# SAMA7D65D2GN8 register map
Vendor: Microchip Technology; Series: SAMA7D6; File version: 0
Registers are 32-bit, read-write, reset 0x0 unless marked. A register's access mark holds for its fields unless they carry their own. Offsets are from the block's base; [hi:lo] are bit positions; 'fields as' and 'values as' point back to an identical list.

## TCPCA — Battery Charging and Type-C Port Controller
Base 0xE083C000; register names take the prefix TCPC_
Same registers: TCPCB 0xE0840000
0x00 VID 16-bit ro reset 0x4D8 — Vendor ID Register
  [15:0] VID — Vendor ID
0x02 PID 16-bit ro reset 0xFFF — Product ID Register
  [15:0] PID — Product ID
0x04 DID 16-bit ro reset 0x100 — Device ID Register
  [15:0] DID — Device ID
0x06 UTCR 16-bit ro reset 0x102 — USB Type-C Rev Register
  [15:0] UTCR — USB Type-C Revision
0x08 UPDR 16-bit ro — USB PD Rev Ver Register
  [15:0] UPDR — USB-PD Specification Revision and Version
0x0A PDIR 16-bit ro reset 0x1012 — PD Interface Rev Register
  [15:0] PDIR — USB-Port Controller Interface Specification Revision
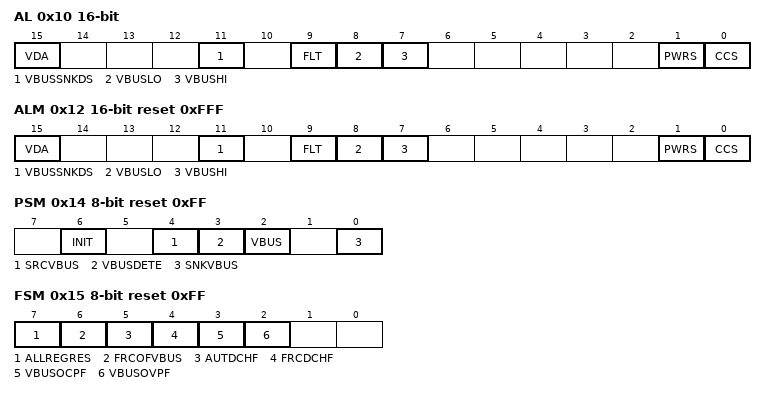
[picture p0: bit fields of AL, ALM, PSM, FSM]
0x10 AL 16-bit — Alert Register
  [15] VDA — Vendor Defined Alert (clear on write '1')
    0=No vendor-defined alert has been detected; 1=A vendor-defined alert has been detected
  [11] VBUSSNKDS — VBUS Sink Disconnect Detected (clear on write '1')
    0=No VBUS sink disconnect threshold crossing has been detected; 1=A VBUS sink disconnect threshold crossing has been detected
  [9] FLT — Fault (clear on write '1')
    0=No fault has occurred; 1=A fault has occurred. Read TCPC_FS.
  [8] VBUSLO — VBUS Voltage Alarm Low (clear on write '1')
    0=A low-voltage alarm has not occurred; 1=A low-voltage alarm has occurred
  [7] VBUSHI — VBUS Voltage Alarm High (clear on write '1')
    0=A high-voltage alarm has not occurred; 1=A high-voltage alarm has occurred
  [1] PWRS — Power Status (clear on write '1')
    0=Power status not changed; 1=Power status changed
  [0] CCS — CC Status (clear on write '1')
    0=CC status not changed; 1=CC status changed
0x12 ALM 16-bit reset 0xFFF — Alert Mask Register
  [15] VDA — Vendor Defined Alert Interrupt Mask
  [11] VBUSSNKDS — VBUS Sink Disconnect Detected Interrupt Mask
  [9] FLT — Fault Interrupt Mask
  [8] VBUSLO — VBUS Voltage Alarm Low Interrupt Mask
  [7] VBUSHI — VBUS Voltage Alarm High Interrupt Mask
  [1] PWRS — Power Status Interrupt Mask
  [0] CCS — CC Status Interrupt Mask
0x14 PSM 8-bit reset 0xFF — Power Status Mask Register
  [6] INIT — TCPC Initialization Interrupt Mask
  [4] SRCVBUS — Sourcing VBUS Interrupt Mask
  [3] VBUSDETE — VBUS Present Detection Interrupt Mask
  [2] VBUS — VBUS Present Interrupt Mask
  [0] SNKVBUS — Sinking VBUS Interrupt Mask
0x15 FSM 8-bit reset 0xFF — Fault Status Mask Register
  [7] ALLREGRES — All Registers Reset To Default Interrupt Mask
  [6] FRCOFVBUS — Force Off VBUS Interrupt Mask
  [5] AUTDCHF — Auto Discharge Failed Interrupt Mask
  [4] FRCDCHF — Force Discharge Failed Interrupt Mask
  [3] VBUSOCPF — Internal or External OCP VBUS Over Current Protection Fault Interrupt Mask
  [2] VBUSOVPF — Internal or External OVP VBUS Over Voltage Protection Fault Interrupt Mask
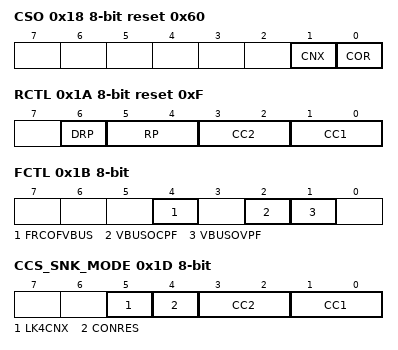
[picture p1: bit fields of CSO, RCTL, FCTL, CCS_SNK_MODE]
0x18 CSO 8-bit reset 0x60 — Config Standard Output Register
  [1] CNX — Connection Present
    0=No connection (default); 1=Connection
  [0] COR — Connector Orientation
    0=Normal (CC1=A5, CC2=B5, TX1=A2/A3, RX1=B10/B11) default; 1=Flipped (CC2=A5, CC1=B5, TX1=B2/B3, RX1=A10/A11)
0x1A RCTL 8-bit reset 0xF — Role Control Register
  [6] DRP — Dual Role Play
    0=No DRP. CC1, CC2 fields determine Rp/Rd/Ra or open settings.; 1=DRP
  [5:4] RP — Resistor for Power Advertising
    0=RP_DEFAULT; 1=RP_1P5A (Rp 1.5A); 2=RP_3A (Rp 3.0A)
  [3:2] CC2 — Configuration Channel 2
    0=CC2_RA (Ra); 1=CC2_RP (Rp defined as in RP field); 2=CC2_RD (Rd); 3=CC2_OPEN (Open (Disconnect or don't care))
  [1:0] CC1 — Configuration Channel 1
    0=CC1_RA (Ra); 1=CC1_RP (Rp defined as in RP field); 2=CC1_RD (Rd); 3=CC1_OPEN (Open (Disconnect or don't care))
0x1B FCTL 8-bit — Fault Control Register
  [4] FRCOFVBUS — Force Off VBUS (Source or Sink)
    0=Allows standard input signal Force Off VBUS control (default); 1=Blocks standard input signal Force Off VBUS control
  [2] VBUSOCPF — Internal or External OCP VBUS Over Current Protection Fault
    0=Internal and external OCP circuit enabled; 1=Internal and external OCP circuit disabled
  [1] VBUSOVPF — Internal or External OVP VBUS Over Voltage Protection Fault
    0=Internal and external OVP circuit enabled; 1=Internal and external OVP circuit disabled
0x1D CCS_SNK_MODE 8-bit ro — CC Status Register
  [5] LK4CNX — Looking4Connection
    0=TCPC is not actively looking for a connection. A transition from '1' to '0' indicates a potential connection has been found.; 1=TCPC is looking for a connection (toggling as a DRP or looking for a connection as sink/source only condition)
  [4] CONRES — Connect Result
    0=TCPC is presenting Rp; 1=TCPC is presenting Rd
  [3:2] CC2 — CC2 State
    0=CC2_SNK_OPEN (SNK.Open (Below maximum vRa)); 1=CC2_SNK_DEFAULT (SNK.Default (Above minimum vRd-Connect)); 2=CC2_SNK_1P5A (SNK.Power1.5 (Above minimum vRd-Connect) Detects Rp-1.5A); 3=CC2_SNK_3A (SNK.Power3.0 (Above minimum vRd-Connect) Detects Rp-3.0A)
  [1:0] CC1 — CC1 State
    0=CC1_SNK_OPEN (SNK.Open (Below maximum vRa)); 1=CC1_SNK_DEFAULT (SNK.Default (Above minimum vRd-Connect)); 2=CC1_SNK_1P5A (SNK.Power1.5 (Above minimum vRd-Connect) Detects Rp-1.5A); 3=CC1_SNK_3A (SNK.Power3.0 (Above minimum vRd-Connect) Detects Rp-3.0A)
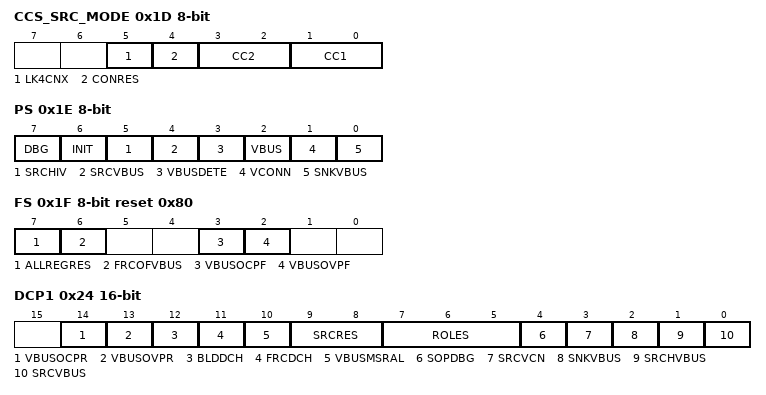
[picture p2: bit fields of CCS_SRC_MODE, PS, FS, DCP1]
0x1D CCS_SRC_MODE 8-bit ro (alternate view of CCS_SNK_MODE) — CC Status Register
  [5] LK4CNX — Looking4Connection
    values as CCS_SNK_MODE.LK4CNX
  [4] CONRES — Connect Result
    0=TCPC is presenting Rp; 1=TCPC is presenting Rd
  [3:2] CC2 — CC2 State
    0=CC2_SRC_OPEN (SRC.Open (Open, Rp)); 1=CC2_SRC_RA (SRC.Ra (below maximum vRa)); 2=CC2_SRC_RD (SRC.Rd (within the vRd range))
  [1:0] CC1 — CC1 State
    0=CC1_SRC_OPEN (SRC.Open (Open, Rp)); 1=CC1_SRC_RA (SRC.Ra (below maximum vRa)); 2=CC1_SRC_RD (SRC.Rd (within the vRd range))
0x1E PS 8-bit ro — Power Status Register
  [7] DBG — Debug Accessory Connected
    0=No debug accessory connected (default)
  [6] INIT — TCPC Initialization
    0=TCPC has completed initialization and all registers are valid; 1=TCPC is still performing internal initialization and the only registers ensuring return of correct values are 00h..0Fh
  [5] SRCHIV — Sourcing High Voltage
    0=VSafe5V
  [4] SRCVBUS — Sourcing VBUS
    0=Sourcing VBUS is disabled; 1=Sourcing VBUS is enabled
  [3] VBUSDETE — VBUS Present Detection Enabled
    0=VBUS present detection disabled; 1=VBUS present detection enabled (default)
  [2] VBUS — VBUS Present
    0=VBUS disconnected; 1=VBUS connected
  [1] VCONN — VCONN Present
    0=VCONN is not present
  [0] SNKVBUS — Sinking VBUS
    0=Sink is disconnected. (Default and if not supported); 1=TCPC is sinking VBUS to the system load
0x1F FS 8-bit reset 0x80 — Fault Status Register
  [7] ALLREGRES — All Registers Reset To Default (clear on write '1')
    0=The registers have not been reset since the last clear of this bit; 1=The TCPC has reset all registers to their default value. This happens at initial power-up or if an unexpected power reset occurs.
  [6] FRCOFVBUS — Force Off VBUS (clear on write '1')
    0=No fault detected, no action (default and not supported); 1=VBUS source/sink has been forced off due to external fault
  [3] VBUSOCPF — Internal or External OCP VBUS Over-Current Protection Fault (clear on write '1')
    0=Not in an over-current protection state; 1=Over-current fault latched
  [2] VBUSOVPF — Internal or External OVP VBUS Over-Voltage Protection Fault (clear on write '1')
    0=Not in an over-voltage protection state; 1=Over-voltage fault latched
0x23 CMD 8-bit — Command Register
  [7:0] COMMAND
    34=DISABLEVBUSDETECT (Disables Vbus present detection.); 51=ENABLEVBUSDETECT (Enables Vbus present detection.); 68=DISABLESINKVBUS (Disables sinking power over VBUS. This COMMAND does not disable TCPC_PS.VBUS detection. The TCPC must clear TCPC_FS.VBUSOCPF and TCPC_FS.VBUSOVPF.); 85=SINKVBUS (Enables sinking power over VBUS and enable VBUS present detection.); 102=DISABLESOURCEVBUS (Disables sourcing power over VBUS. The TCPC shall stop reporting TCPC_FS. Internal or External OCP or OVP Faults. This COMMAND does not disable TCPC_PS.VBUS detection.); 119=SOURCEVBUSDEFAULTVOLTAGE (Enables sourcing vSafe5V over VBUS and enable VBUS present detection. Source must transition to vSafe5V if at a high voltage.); 153=LOOK4CONNECTION (Starts DRP toggling if TCPC_RCTL.DRP=1b. If TCPC_RCTL.CC1/CC2= 01b start with Rp, if TCPC_RCTL.CC1/CC2 =10b start with Rd. If TCPC_RCTL.CC1/CC2 are not both 01b or 10b, then do not start toggling. The TCPM must issue TCPC_CMD.Look4Connection to enable the TCPC to restart connection detection in cases where TCPC_RCTL contents will not change. An example of this is when a potential connection as a source occurred but was further debounced by the TCPM to find the sink disconnected. In this case, a source only or DRP should go back to its Unattached.Src state. This would result in TCPC_RCTL staying the same.)
0x24 DCP1 16-bit — Device Capabilities 1 Register
  [14] VBUSOCPR — VBUS OCP Reporting
    0=VBUS OCP is not reported by the TCPC; 1=VBUS OCP is reported by the TCPC
  [13] VBUSOVPR — VBUS OVP Reporting
    0=VBUS OVP is not reported by the TCPC; 1=VBUS OVP is reported by the TCPC
  [12] BLDDCH — Bleed Discharge
    0=No bleed discharge implemented in TCPC; 1=Bleed discharge is implemented in the TCPC
  [11] FRCDCH — Force Discharge
    0=No force discharge implemented in TCPC; 1=Force discharge is implemented in the TCPC
  [10] VBUSMSRAL — VBUS Measurement and Alarm Capable
    0=No VBUS voltage measurement nor VBUS alarms; 1=VBUS voltage measurement and VBUS alarms
  [9:8] SRCRES — Source Resistor Supported
    0=RES_RPDEF (Rp default only); 1=RES_RP1P5 (Rp 1.5A and default); 2=RES_RP3 (Rp 3.0A, 1.5A, and default)
  [7:5] ROLES — Roles Supported
    0=ROLE_SRCSNK (USB Type-C Port Manager can configure the Port as Source only or Sink only (not DRP)); 1=ROLE_SRC (Source only); 2=ROLE_SNK (Sink only); 3=ROLE_SNK_ACC (Sink with accessory support); 4=ROLE_DRP (DRP only); 5=ROLE_ALL (Source, Sink, DRP, Adapter/Cable all supported); 6=ROLE_SRCSNKDRP (Source, Sink, DRP); 7=ROLE_INVALID (Not valid)
  [4] SOPDBG — SOP'_DBG/SOP''_DBG Support
  [3] SRCVCN — Source VCONN
    0=TCPC is not capable of switching VCONN; 1=TCPC is capable of switching VCONN
  [2] SNKVBUS — Sink VBUS
    0=TCPC is not capable controlling the sink path to the system load; 1=TCPC is capable of controlling the sink path to the system load
  [1] SRCHVBUS — Source High Voltage VBUS
    0=TCPC is not capable of controlling the source high voltage path to VBUS; 1=TCPC is capable of controlling the source high voltage path to VBUS
  [0] SRCVBUS — Source VBUS
    0=TCPC is not capable of controlling the source path to VBUS; 1=TCPC is capable of controlling the source path to VBUS
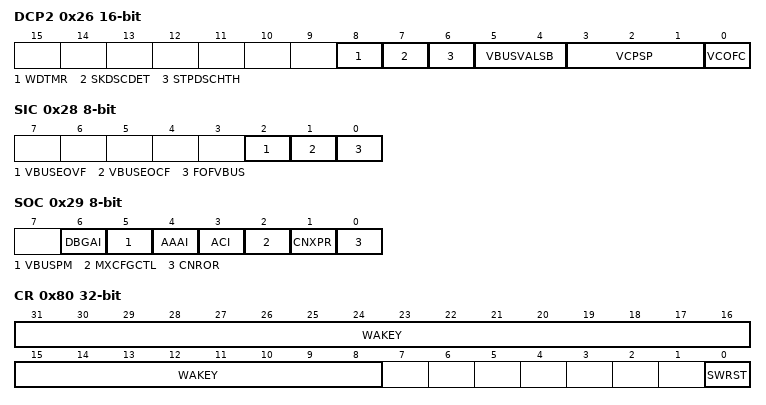
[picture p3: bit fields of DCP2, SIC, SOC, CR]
0x26 DCP2 16-bit — Device Capabilities 2 Register
  [8] WDTMR — Watchdog Timer
    0=Enable Watchdog Timer not implemented; 1=Enable Watchdog Timer implemented
  [7] SKDSCDET — Sink Disconnect Detection
    0=VBUS_SINK_DISCONNECT_THRESHOLD not implemented (default: Use TCPC_PS.VBUS=0b to indicate a Sink disconnect); 1=VBUS_SINK_DISCONNECT_THRESHOLD implemented
  [6] STPDSCHTH — Stop Discharge Threshold
  [5:4] VBUSVALSB — VBUS Voltage Alarm LSB
  [3:1] VCPSP — VCONN Power Supported
  [0] VCOFC — VCONN Overcurrent Fault Capable
0x28 SIC 8-bit — Standard Input Capabilities Register
  [all] fields
    0=Not present in TCPC; 1=Present in TCPC
  [2] VBUSEOVF — VBUS External Over-Voltage Fault
  [1] VBUSEOCF — VBUS External Over-Current Fault
  [0] FOFVBUS — Force Off VBUS (Source or Sink)
0x29 SOC 8-bit — Standard Output Capabilities Register
  [6] DBGAI — Debug Accessory Indicator
    0=Not present in TCPC; 1=Present in TCPC
  [5] VBUSPM — VBUS Present Monitor
    0=Not present in TCPC; 1=Present in TCPC
  [4] AAAI — Audio Adapter Accessory Indicator
    0=Not present in TCPC; 1=Present in TCPC
  [3] ACI — Active Cable Indicator
    0=Not present in TCPC; 1=Present in TCPC
  [2] MXCFGCTL — MUX Configuration Control
    0=Not present in TCPC; 1=Present in TCPC
  [1] CNXPR — Connection Present
    0=No connection; 1=Connection
  [0] CNROR — Connector Orientation
    0=Not present in TCPC; 1=Present in TCPC
0x80 CR wo — Control Register
  [31:8] WAKEY — Register Write Access Key
    0x544343=PASSWD (Writing any other value in this field aborts the write operation.)
  [0] SWRST — Software Reset
    0=Aborts the write operation; 1=Resets the TCPC. A software-triggered hardware reset of the TCPC interface is performed.
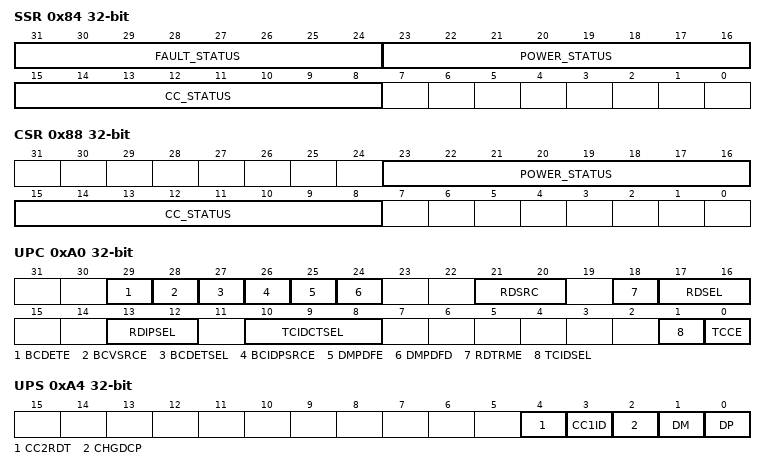
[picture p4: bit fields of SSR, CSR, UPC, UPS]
0x84 SSR wo — Set Status Register
  [31:24] FAULT_STATUS — Fault Status Register Set
    0=No effect; 1=Sets the corresponding bit in TCPC_FS and the FLT_ST bit in TCPC_AL
  [23:16] POWER_STATUS — Power Status Register Set
    0=No effect; 1=Sets the corresponding bit in TCPC_PS and the PWR_ST bit in TCPC_AL
  [15:8] CC_STATUS — CC Status Register Set
    0=No effect; 1=Sets the corresponding bit in TCPC_CCS and the CC_ST bit in TCPC_AL
0x88 CSR wo — Clear Status Register
  [23:16] POWER_STATUS — Power Status Register Clear
    0=No effect; 1=Clears the corresponding bit in TCPC_PS
  [15:8] CC_STATUS — CC Status Register Clear
    0=No effect; 1=Clears the corresponding bit in TCPC_CCS
0x8C SAR wo — Set Alert Register
  [15:0] ALERT — Alert Register Set
    0=No effect; 1=Sets the corresponding bit in TCPC_AL
0xA0 UPC — USB PHY Control Register
  [29] BCDETE — Battery Charging Detection Enable
    0=Battery charging detection is disabled; 1=Battery charging detection is enabled
  [28] BCVSRCE — Battery Charging Voltage Source Enable
    0=Battery charging VDP_SRC and VDM_SRC voltage sources are disabled; 1=Battery charging voltage source enable:
  [27] BCDETSEL — Battery Charging Detection Selection
    0=Battery charging primary detection is selected; 1=Battery charging secondary detection is selected
  [26] BCIDPSRCE — Battery Charging IDP Source Enable
    0=Battery charging IDP current source is disabled; 1=Battery charging IDP current source is enabled for data contact detection
  [25] DMPDFE — DM Pull-down Force Enable
    0=DM pull-down is not forced to the active state by the TCPC; 1=DM pull-down is forced to the active state by the TCPC for battery charging data contact detection
  [24] DMPDFD — DM Pull-down Force Disable
    0=DM pull-down is not forced to the inactive state by the TCPC; 1=DM pull-down is forced to the inactive state by the TCPC
  [21:20] RDSRC — Type-C Rd Resistor Value Source
    0=RDSRC_CFG (Software configuration value RDSEL is selected for Rd pull-down resistor.); 1=RDSRC_OTP (OTP value is selected for Rd pull-down resistor.); 2=RDSRC_CAL (Calibration value TCPC_CALST.RDCAL is selected for Rd pull-down resistor.); 3=RDSRC_DIS (Rd pull-down is disabled.)
  [18] RDTRME — Type-C Rd Resistor Trim Enable
    0=Rd resistor software trim is disabled. The Rd resistor pull-down can be used for Type-C attach detection.; 1=Rd resistor software trim is enabled. CC2 is disconnected. RDSEL is enforced for Rd resistor value.
  [17:16] RDSEL — Type-C Rd Resistor Trim Selection
    0=RDSEL_OFF (Rd pull-down is disabled.); 1=RDSEL_MINUS_10P (Rd pull-down resistor value decreased by 10% is selected.); 2=RDSEL_DEFAULT (Rd pull-down resistor default value is selected.); 3=RDSEL_PLUS_10P (Rd pull-down resistor value increased by 10% is selected.)
  [13:12] RDIPSEL — Type-C Rd or Ip Pull-up Current Selection
    0=IP_OFF (Type-C pull-up current source Ip is off, Rd pull-down is selected); 1=IP_0P5 (Type-C pull-up current source Ip is advertising 0.5A as VBUS sourcing capability); 2=IP_1P5 (Type-C pull-up current source Ip is advertising 1.5A as VBUS sourcing capability); 3=IP_3P0 (Type-C pull-up current source Ip is advertising 3.0A as VBUS sourcing capability)
  [10:8] TCIDCTSEL — Type-C or ID Comparator Threshold Selection
    0=THRESHOLD_0 (Threshold above VRid_gnd for ID determination or Type-C vRa); 1=THRESHOLD_1 (Threshold above VRid_c for ID determination or Type-C vRd-USB); 2=THRESHOLD_2 (Threshold above VRid_b for ID determination or Type-C vRd-1.5); 3=THRESHOLD_3 (Threshold above VRid_a for ID determination or Type-C vRd)
  [1] TCIDSEL — Type-C or ID Selection
    0=CC1 comparator is used for ID detection for OTG or for Battery Charging. CC1 is connected and CC2 is disconnected.; 1=CC1 and CC2 comparators are used to determine the power capability advertised by the facing source
  [0] TCCE — Type-C Cell Enable
    0=USB Type-C cell is disabled; CC1 and CC2 are disconnected; 1=USB Type-C cell is enabled
0xA4 UPS ro — USB PHY Status Register
  [4] CC2RDT — Type-C CC2 Comparator or Rd Trim Comparator
    0=The CC2 or Rd Trim comparator output is low. Voltage is below the selected TCUPC.TCIDCTSEL threshold.; 1=The CC2 or Rd Trim comparator output is high. Voltage is above the selected TCUPC.TCIDCTSEL threshold.
  [3] CC1ID — Type-C CC1 Comparator or ID Comparator
    0=The CC1 or ID comparator output is low. Voltage is below the selected TCPC_UPC.TCIDCTSEL threshold.; 1=The CC1 or ID comparator output is high. Voltage is above the selected TCPC_UPC.TCIDCTSEL threshold.
  [2] CHGDCP — Charging Port Detection, Dedicated Charging Port Detection
    0=No charging port detected; 1=Charging port detected
  [1] DM — USB Differential line Minus
    0=DM is low; 1=DM is high
  [0] DP — USB Differential line Plus
    0=DP is low; 1=DP is high
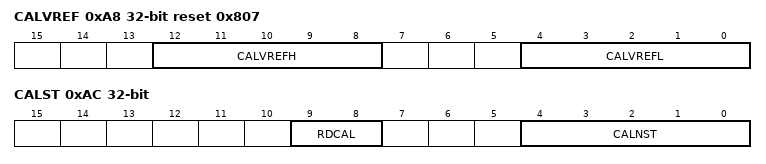
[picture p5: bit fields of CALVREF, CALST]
0xA8 CALVREF reset 0x807 — Calibration Voltage Reference Register
  [12:8] CALVREFH — Calibration Voltage Reference High Value
  [4:0] CALVREFL — Calibration Voltage Reference Low Value
0xAC CALST ro — Calibration Status Register
  [9:8] RDCAL — Rd From Calibration
  [4:0] CALNST — Calibration Input Status
0xB0 CALIST ro — Calibration Interrupt Status Register
  [0] CALNIST — Calibration Interrupt Status
    0=No TCPC calibration input change has occurred in TCPC_CALST since the last read of the TCPC_CALIST register; 1=At least one TCPC calibration input change has occurred in TCPC_CALST since the last read of the TCPC_CALIST register
0xB4 CALIM — Calibration Interrupt Mask Register
  [0] CALIM — Calibration Interrupt Mask
    0=The TCPC calibration interrupt status TCPC_CALIST.CALIST does not trigger any TCPC interrupt when set; 1=The TCPC calibration interrupt status TCPC_CALIST.CALIST triggers the TCPC interrupt line when set
